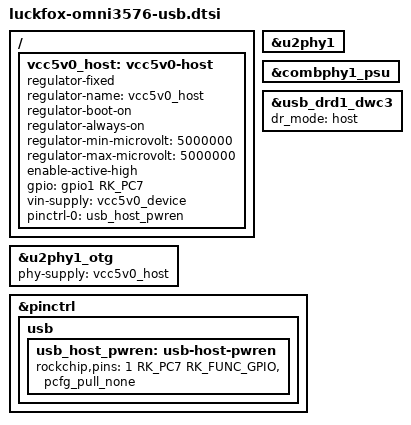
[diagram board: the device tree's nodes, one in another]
// SPDX-License-Identifier: (GPL-2.0+ OR MIT)
/*
 * Copyright (c) 2024 Luckfox Technology Co., Ltd.
 *
 */

// #include "luckfox-core3576.dtsi"
#include <dt-bindings/gpio/gpio.h>

/ {
	vcc5v0_host: vcc5v0-host {
		compatible = "regulator-fixed";
		regulator-name = "vcc5v0_host";
		regulator-boot-on;
		regulator-always-on;
		regulator-min-microvolt = <5000000>;
		regulator-max-microvolt = <5000000>;
		enable-active-high;
		gpio = <&gpio1 RK_PC7 GPIO_ACTIVE_HIGH>;
		vin-supply = <&vcc5v0_device>;
		pinctrl-names = "default";
		pinctrl-0 = <&usb_host_pwren>;
	};
};

&u2phy1 {
	status = "okay";
};
&u2phy1_otg {
	phy-supply = <&vcc5v0_host>;
	status = "okay";
};

&combphy1_psu {
	status = "okay";
};
&usb_drd1_dwc3 {
	dr_mode = "host";
	status = "okay";
};

&pinctrl {
	usb {
		usb_host_pwren: usb-host-pwren {
			rockchip,pins = <1 RK_PC7 RK_FUNC_GPIO &pcfg_pull_none>;
		};
	};
};
